# SERDES_16G0 register map
Vendor: Texas Instruments
Peripheral module from a debugger description file (folder J7ES).
Registers are 32-bit, read-write, reset 0x0 unless marked. A register's access mark holds for its fields unless they carry their own. Offsets are as the file gives them; lines under a group give offsets from that group; [hi:lo] are bit positions; {n}, {i} and the like mark numbered series; 'fields as' and 'values as' point back to an identical list; <NAME> marks a mode.

## SERDES_16G0 (part 1 of 5)
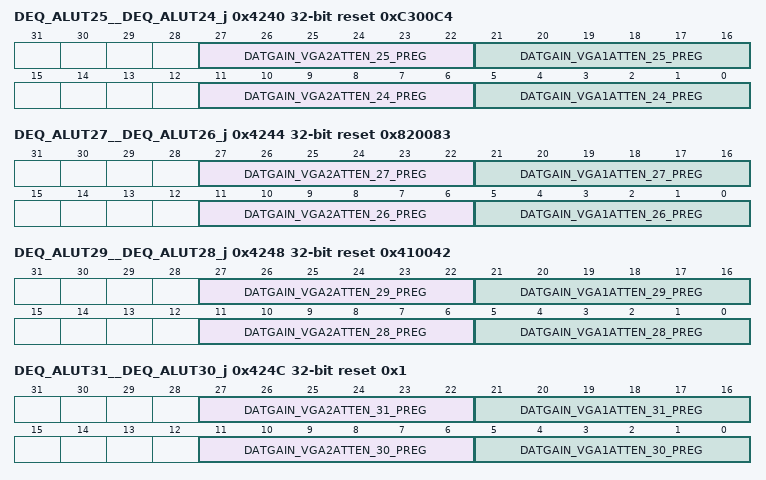
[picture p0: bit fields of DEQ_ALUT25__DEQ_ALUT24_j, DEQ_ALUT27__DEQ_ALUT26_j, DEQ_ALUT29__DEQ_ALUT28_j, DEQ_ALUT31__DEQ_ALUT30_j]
0x4240 DEQ_ALUT25__DEQ_ALUT24_j reset 0xC300C4 — Receive data path equalization LUT attenuation, entry 24 register. Offset = 4240h + (j * 400h); where j = 0h to 1h
  [27:22] DATGAIN_VGA2ATTEN_25_PREG — Receive data path equalization LUT VGA2 attenuation control, entry 25
  [21:16] DATGAIN_VGA1ATTEN_25_PREG — Receive data path equalization LUT VGA1 attenuation control, entry 25
  [11:6] DATGAIN_VGA2ATTEN_24_PREG — Receive data path equalization LUT VGA2 attenuation control, entry 24
  [5:0] DATGAIN_VGA1ATTEN_24_PREG — Receive data path equalization LUT VGA1 attenuation control, entry 24
0x4244 DEQ_ALUT27__DEQ_ALUT26_j reset 0x820083 — Receive data path equalization LUT attenuation, entry 26 register. Offset = 4244h + (j * 400h); where j = 0h to 1h
  [27:22] DATGAIN_VGA2ATTEN_27_PREG — Receive data path equalization LUT VGA2 attenuation control, entry 27
  [21:16] DATGAIN_VGA1ATTEN_27_PREG — Receive data path equalization LUT VGA1 attenuation control, entry 27
  [11:6] DATGAIN_VGA2ATTEN_26_PREG — Receive data path equalization LUT VGA2 attenuation control, entry 26
  [5:0] DATGAIN_VGA1ATTEN_26_PREG — Receive data path equalization LUT VGA1 attenuation control, entry 26
0x4248 DEQ_ALUT29__DEQ_ALUT28_j reset 0x410042 — Receive data path equalization LUT attenuation, entry 28 register. Offset = 4248h + (j * 400h); where j = 0h to 1h
  [27:22] DATGAIN_VGA2ATTEN_29_PREG — Receive data path equalization LUT VGA2 attenuation control, entry 29
  [21:16] DATGAIN_VGA1ATTEN_29_PREG — Receive data path equalization LUT VGA1 attenuation control, entry 29
  [11:6] DATGAIN_VGA2ATTEN_28_PREG — Receive data path equalization LUT VGA2 attenuation control, entry 28
  [5:0] DATGAIN_VGA1ATTEN_28_PREG — Receive data path equalization LUT VGA1 attenuation control, entry 28
0x424C DEQ_ALUT31__DEQ_ALUT30_j reset 0x1 — Receive data path equalization LUT attenuation, entry 30 register. Offset = 424Ch + (j * 400h); where j = 0h to 1h
  [27:22] DATGAIN_VGA2ATTEN_31_PREG — Receive data path equalization LUT VGA2 attenuation control, entry 31
  [21:16] DATGAIN_VGA1ATTEN_31_PREG — Receive data path equalization LUT VGA1 attenuation control, entry 31
  [11:6] DATGAIN_VGA2ATTEN_30_PREG — Receive data path equalization LUT VGA2 attenuation control, entry 30
  [5:0] DATGAIN_VGA1ATTEN_30_PREG — Receive data path equalization LUT VGA1 attenuation control, entry 30
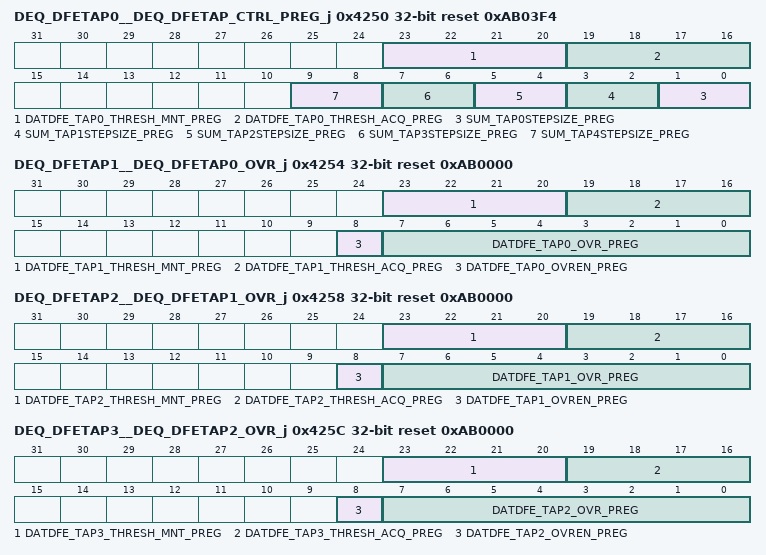
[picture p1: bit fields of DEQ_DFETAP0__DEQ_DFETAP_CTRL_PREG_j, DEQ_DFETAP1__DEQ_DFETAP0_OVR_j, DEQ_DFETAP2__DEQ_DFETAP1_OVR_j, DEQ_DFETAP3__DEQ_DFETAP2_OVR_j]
0x4250 DEQ_DFETAP0__DEQ_DFETAP_CTRL_PREG_j reset 0xAB03F4 — Receive data path DFE tap control register. Offset = 4250h + (j * 400h); where j = 0h to 1h
  [23:20] DATDFE_TAP0_THRESH_MNT_PREG — Receive data path DFE tap 0 accumulator threshold for maintenance.
  [19:16] DATDFE_TAP0_THRESH_ACQ_PREG — Receive data path DFE tap 0 accumulator threshold for acquisition.
  [2n+1:2n] SUM_TAP{n}STEPSIZE_PREG (n=0..4) — Receive data path DFE tap {n} feedback current trim:
0x4254 DEQ_DFETAP1__DEQ_DFETAP0_OVR_j reset 0xAB0000 — Receive data path DFE tap 0 override register. Offset = 4254h + (j * 400h); where j = 0h to 1h
  [23:20] DATDFE_TAP1_THRESH_MNT_PREG — Receive data path DFE tap 1 accumulator threshold for maintenance.
  [19:16] DATDFE_TAP1_THRESH_ACQ_PREG — Receive data path DFE tap 1 accumulator threshold for acquisition.
  [8] DATDFE_TAP0_OVREN_PREG — Receive data path DFE tap 0 weight active high override enable.
  [7:0] DATDFE_TAP0_OVR_PREG — When datdfe_tap0_ovren_preg is asserted high, this value overrides the tap 0 weight.
0x4258 DEQ_DFETAP2__DEQ_DFETAP1_OVR_j reset 0xAB0000 — Receive data path DFE tap 1 override register. Offset = 4258h + (j * 400h); where j = 0h to 1h
  [23:20] DATDFE_TAP2_THRESH_MNT_PREG — Receive data path DFE tap 2 accumulator threshold for maintenance.
  [19:16] DATDFE_TAP2_THRESH_ACQ_PREG — Receive data path DFE tap 2 accumulator threshold for acquisition.
  [8] DATDFE_TAP1_OVREN_PREG — Receive data path DFE tap 1 weight active high override enable.
  [7:0] DATDFE_TAP1_OVR_PREG — When datdfe_tap1_ovren_preg is asserted high, this value overrides the tap 1 weight.
0x425C DEQ_DFETAP3__DEQ_DFETAP2_OVR_j reset 0xAB0000 — Receive data path DFE tap 2 override register. Offset = 425Ch + (j * 400h); where j = 0h to 1h
  [23:20] DATDFE_TAP3_THRESH_MNT_PREG — Receive data path DFE tap 3 accumulator threshold for maintenance.
  [19:16] DATDFE_TAP3_THRESH_ACQ_PREG — Receive data path DFE tap 3 accumulator threshold for acquisition.
  [8] DATDFE_TAP2_OVREN_PREG — Receive data path DFE tap 2 weight active high override enable.
  [7:0] DATDFE_TAP2_OVR_PREG — When datdfe_tap2_ovren_preg is asserted high, this value overrides the tap 2 weight.
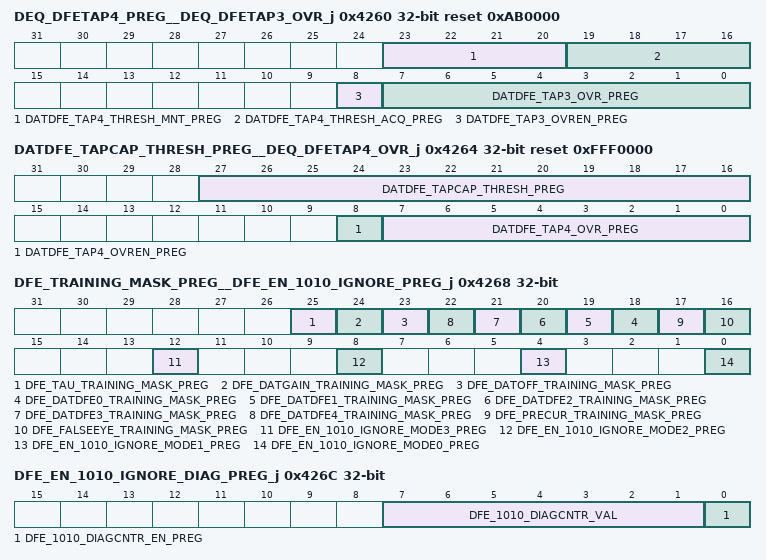
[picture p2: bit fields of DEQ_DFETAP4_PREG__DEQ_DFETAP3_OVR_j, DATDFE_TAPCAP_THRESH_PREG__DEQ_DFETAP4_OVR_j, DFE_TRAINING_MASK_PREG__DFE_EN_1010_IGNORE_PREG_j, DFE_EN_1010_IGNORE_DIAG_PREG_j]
0x4260 DEQ_DFETAP4_PREG__DEQ_DFETAP3_OVR_j reset 0xAB0000 — Receive data path DFE tap 3 override register. Offset = 4260h + (j * 400h); where j = 0h to 1h
  [23:20] DATDFE_TAP4_THRESH_MNT_PREG — Receive data path DFE tap 4 accumulator threshold for maintenance.
  [19:16] DATDFE_TAP4_THRESH_ACQ_PREG — Receive data path DFE tap 4 accumulator threshold for acquisition.
  [8] DATDFE_TAP3_OVREN_PREG — Receive data path DFE tap 3 weight active high override enable.
  [7:0] DATDFE_TAP3_OVR_PREG — When datdfe_tap3_ovren_preg is asserted high, this value overrides the tap 3 weight.
0x4264 DATDFE_TAPCAP_THRESH_PREG__DEQ_DFETAP4_OVR_j reset 0xFFF0000 — Receive data path DFE tap 4 override register. Offset = 4264h + (j * 400h); where j = 0h to 1h
  [27:16] DATDFE_TAPCAP_THRESH_PREG — Threshold for capping the sum of the receive data path DFE tap magnitudes.
  [8] DATDFE_TAP4_OVREN_PREG — Receive data path DFE tap 4 weight active high override enable.
  [7:0] DATDFE_TAP4_OVR_PREG — When datdfe_tap4_ovren_preg is asserted high, this value overrides the tap 4 weight.
0x4268 DFE_TRAINING_MASK_PREG__DFE_EN_1010_IGNORE_PREG_j — DFE_TRAINING_MASK_PREG__DFE_EN_1010_IGNORE_PREG Offset = 4268h + (j * 400h); where j = 0h to 1h
  [25] DFE_TAU_TRAINING_MASK_PREG — When set to 1'b0, the tau training will be paused during rx_eq_training_data_valid deassertion and during detection of 1010 pattern occurs with dfe_en_1010_ignore_modeX_preg is asserted.
  [24] DFE_DATGAIN_TRAINING_MASK_PREG — When set to 1'b0, the data path gain training will be paused during rx_eq_training_data_valid deassertion and during detection of 1010 pattern occurs with dfe_en_1010_ignore_modeX_preg is asserted.
  [23] DFE_DATOFF_TRAINING_MASK_PREG — When set to 1'b0, the data path offset training will be paused during rx_eq_training_data_valid deassertion and during detection of 1010 pattern occurs with dfe_en_1010_ignore_modeX_preg is asserted.
  [n+18] DFE_DATDFE{n}_TRAINING_MASK_PREG (n=0..4) — When set to 1'b0, the DFE tap {n} training will be paused during rx_eq_training_data_valid deassertion and during detection of 1010 pattern occurs with dfe_en_1010_ignore_modeX_preg is asserted.
  [17] DFE_PRECUR_TRAINING_MASK_PREG — When set to 1'b0, the far-end transmit pre cursor training will be paused during rx_eq_training_data_valid deassertion and during detection of 1010 pattern occurs with dfe_en_1010_ignore_modeX_preg is asserted.
  [16] DFE_FALSEEYE_TRAINING_MASK_PREG — When set to 1'b0, false eye detection will be paused during rx_eq_training_data_valid deassertion and during detection of 1010 pattern occurs with dfe_en_1010_ignore_modeX_preg is asserted.
  [12] DFE_EN_1010_IGNORE_MODE3_PREG — Active high enable for the DFE ignore 1010 function when xcvr_standard_mode_ln_{15:0}[2:0] is 3'b011.
  [8] DFE_EN_1010_IGNORE_MODE2_PREG — Active high enable for the DFE ignore 1010 function when xcvr_standard_mode_ln_{15:0}[2:0] is 3'b010.
  [4] DFE_EN_1010_IGNORE_MODE1_PREG — Active high enable for the DFE ignore 1010 function when xcvr_standard_mode_ln_{15:0}[2:0] is 3'b001
  [0] DFE_EN_1010_IGNORE_MODE0_PREG — Active high enable for the DFE ignore 1010 function when xcvr_standard_mode_ln_{15:0}[2:0] is 3'b000.
0x426C DFE_EN_1010_IGNORE_DIAG_PREG_j access per field — DFE_EN_1010_IGNORE_DIAG_PREG Offset = 426Ch + (j * 400h); where j = 0h to 1h
  [7:1] DFE_1010_DIAGCNTR_VAL ro — Indicates how many 1010.. or 0101.. pattern words are detected
  [0] DFE_1010_DIAGCNTR_EN_PREG rw — Level sensitive diagnostic bit: When de-asserted, counter will be cleared and will not advance.
0x4270 DEQ_PRECUR_PREG_j reset 0x8 — Receive data path far-end transmit precursor equalization control register. Offset = 4270h + (j * 400h); where j = 0h to 1h
  [3:0] PRECUR_THRESH_PREG — Receive data path far-end transmit precursor equalization accumulator threshold.
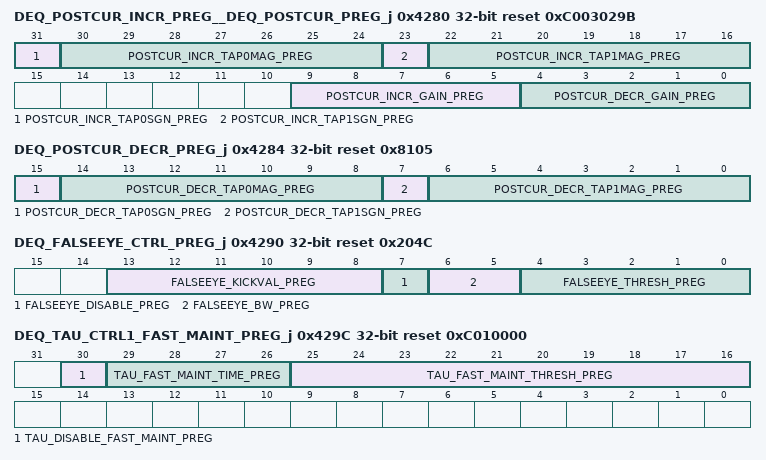
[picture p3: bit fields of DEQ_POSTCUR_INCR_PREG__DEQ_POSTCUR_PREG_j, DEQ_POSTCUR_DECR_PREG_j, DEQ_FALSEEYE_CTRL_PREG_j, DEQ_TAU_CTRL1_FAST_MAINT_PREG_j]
0x4280 DEQ_POSTCUR_INCR_PREG__DEQ_POSTCUR_PREG_j reset 0xC003029B — Receive data path far-end transmit postcursor equalization control register. Offset = 4280h + (j * 400h); where j = 0h to 1h
  [31] POSTCUR_INCR_TAP0SGN_PREG — Receive data path far-end transmit postcursor equalization increment request tap 0 threshold sign.
  [30:24] POSTCUR_INCR_TAP0MAG_PREG — Receive data path far-end transmit postcursor equalization increment request tap 0 threshold unsigned binary encoded magnitude.
  [23] POSTCUR_INCR_TAP1SGN_PREG — Receive data path far-end transmit postcursor equalization increment request tap 1 threshold sign.
  [22:16] POSTCUR_INCR_TAP1MAG_PREG — Receive data path far-end transmit postcursor equalization increment request tap 1 threshold unsigned binary encoded magnitude.
  [9:5] POSTCUR_INCR_GAIN_PREG — Receive data path far-end transmit postcursor equalization increment request gain threshold.
  [4:0] POSTCUR_DECR_GAIN_PREG — Receive data path far-end transmit postcursor equalization decrement request gain threshold.
0x4284 DEQ_POSTCUR_DECR_PREG_j reset 0x8105 — Receive data path far-end transmit postcursor equalization decrement control register. Offset = 4284h + (j * 400h); where j = 0h to 1h
  [15] POSTCUR_DECR_TAP0SGN_PREG — Receive data path far-end transmit postcursor equalization decrement request tap 0 threshold sign.
  [14:8] POSTCUR_DECR_TAP0MAG_PREG — Receive data path far-end transmit postcursor equalization decrement request tap 0 threshold unsigned binary encoded magnitude.
  [7] POSTCUR_DECR_TAP1SGN_PREG — Receive data path far-end transmit postcursor equalization decrement request tap 1 threshold sign.
  [6:0] POSTCUR_DECR_TAP1MAG_PREG — Receive data path far-end transmit postcursor equalization decrement request tap 1 threshold unsigned binary encoded magnitude.
0x4290 DEQ_FALSEEYE_CTRL_PREG_j reset 0x204C — Receive data path equalization (DEQ) false eye control register. Offset = 4290h + (j * 400h); where j = 0h to 1h
  [13:8] FALSEEYE_KICKVAL_PREG — Receive data path equalization (DEQ) false eye detection phase kick amplitude.
  [7] FALSEEYE_DISABLE_PREG — Receive data path equalization (DEQ) false eye detection active high disable.
  [6:5] FALSEEYE_BW_PREG — Receive data path equalization (DEQ) false eye detection bandwidth selection.
  [4:0] FALSEEYE_THRESH_PREG — Receive data path equalization (DEQ) false eye detection binary encoded threshold.
0x429C DEQ_TAU_CTRL1_FAST_MAINT_PREG_j reset 0xC010000 — Receive data path equalization (DEQ) fast maintenance tau training control register 1. Offset = 429Ch + (j * 400h); where j = 0h to 1h
  [30] TAU_DISABLE_FAST_MAINT_PREG — Receive data path equalization (DEQ) fast maintenance tau algorithm active high disable.
  [29:26] TAU_FAST_MAINT_TIME_PREG — Receive data path equalization (DEQ) fast maintenance tau algorithm accumulation time.
  [25:16] TAU_FAST_MAINT_THRESH_PREG — Receive data path equalization (DEQ) fast maintainance tau algorithm accumulation threshold.
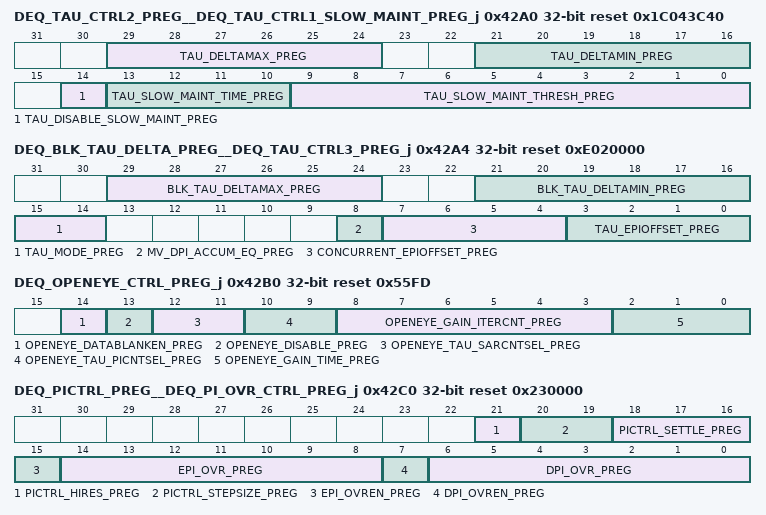
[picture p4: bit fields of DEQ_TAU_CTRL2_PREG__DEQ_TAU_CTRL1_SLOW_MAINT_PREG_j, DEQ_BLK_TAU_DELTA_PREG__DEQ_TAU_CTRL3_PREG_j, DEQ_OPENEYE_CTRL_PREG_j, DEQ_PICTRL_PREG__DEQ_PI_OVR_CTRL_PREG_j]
0x42A0 DEQ_TAU_CTRL2_PREG__DEQ_TAU_CTRL1_SLOW_MAINT_PREG_j reset 0x1C043C40 — Receive data path equalization (DEQ) slow maintenance tau training control register 1. Offset = 42A0h + (j * 400h); where j = 0h to 1h
  [29:24] TAU_DELTAMAX_PREG — Receive data path equalization (DEQ) tau algorithm maximum delta from EPI to DPI.
  [21:16] TAU_DELTAMIN_PREG — Receive data path equalization (DEQ) tau algorithm minimum delta from EPI to DPI.
  [14] TAU_DISABLE_SLOW_MAINT_PREG — Receive data path equalization (DEQ) slow maintenance tau algorithm active high disable.
  [13:10] TAU_SLOW_MAINT_TIME_PREG — Receive data path equalization (DEQ) slow maintenance tau algorithm accumulation time
  [9:0] TAU_SLOW_MAINT_THRESH_PREG — Receive data path equalization (DEQ) slow maintenance tau algorithm accumulation threshold.
0x42A4 DEQ_BLK_TAU_DELTA_PREG__DEQ_TAU_CTRL3_PREG_j reset 0xE020000 — DEQ_BLK_TAU_DELTA_PREG__DEQ_TAU_CTRL3_PREG Offset = 42A4h + (j * 400h); where j = 0h to 1h
  [29:24] BLK_TAU_DELTAMAX_PREG — Receive data path equalization (DEQ) tau algorithm's maximum delta from EPI to DPI used for block TAU acquisition and apparent center.
  [21:16] BLK_TAU_DELTAMIN_PREG — Receive data path equalization (DEQ) tau algorithm's minimum delta from EPI to DPI used for block TAU acquisition and apparent center.
  [15:14] TAU_MODE_PREG — TAU mode register
  [8] MV_DPI_ACCUM_EQ_PREG — Move DPI to the left if (r_accum_a is equal to r_accum_b) and (r_delta is less than equal to tau_deltamin_preg) if this bit is set to 1'b1, else don't move DPI.
  [7:4] CONCURRENT_EPIOFFSET_PREG — Receive data path equalization (DEQ) tau algorithm 4 bit signed offset for EPI used in concurrent, eyesurf, and rx margining.
  [3:0] TAU_EPIOFFSET_PREG — Receive data path equalization (DEQ) tau algorithm 4 bit signed offset for EPI used tau opertions.
0x42B0 DEQ_OPENEYE_CTRL_PREG_j reset 0x55FD — Receive data path equalization (DEQ) open eye algorithms control register. Offset = 42B0h + (j * 400h); where j = 0h to 1h
  [14] OPENEYE_DATABLANKEN_PREG — Receive data path equalization (DEQ) open eye data blank active high enable.
  [13] OPENEYE_DISABLE_PREG — Receive data path equalization (DEQ) open eye tau algorithm active high disable.
  [12:11] OPENEYE_TAU_SARCNTSEL_PREG — Receive data path equalization (DEQ) open eye tau algorithm SAR count selection.
  [10:9] OPENEYE_TAU_PICNTSEL_PREG — Receive data path equalization (DEQ) open eye tau algorithm PI step count selection.
  [8:3] OPENEYE_GAIN_ITERCNT_PREG — Open eye gain iteration count
  [2:0] OPENEYE_GAIN_TIME_PREG — Open eye gain accumulation time.
0x42C0 DEQ_PICTRL_PREG__DEQ_PI_OVR_CTRL_PREG_j reset 0x230000 — Receive data path equalization (DEQ) PI override register. Offset = 42C0h + (j * 400h); where j = 0h to 1h
  [21] PICTRL_HIRES_PREG — DPI and EPI high resolution enable:
  [20:19] PICTRL_STEPSIZE_PREG — DPI and EPI step size selection.
  [18:16] PICTRL_SETTLE_PREG — DPI and EPI control settling time.
  [15] EPI_OVREN_PREG — EPI phase active high override enable.
  [14:8] EPI_OVR_PREG — When epi_ovren_preg is asserted high, this value will override the data path EPI binary phase.
  [7] DPI_OVREN_PREG — DPI phase active high override enable.
  [6:0] DPI_OVR_PREG — When dpi_ovren_preg is asserted high, this value will override the data path DPI binary phase.
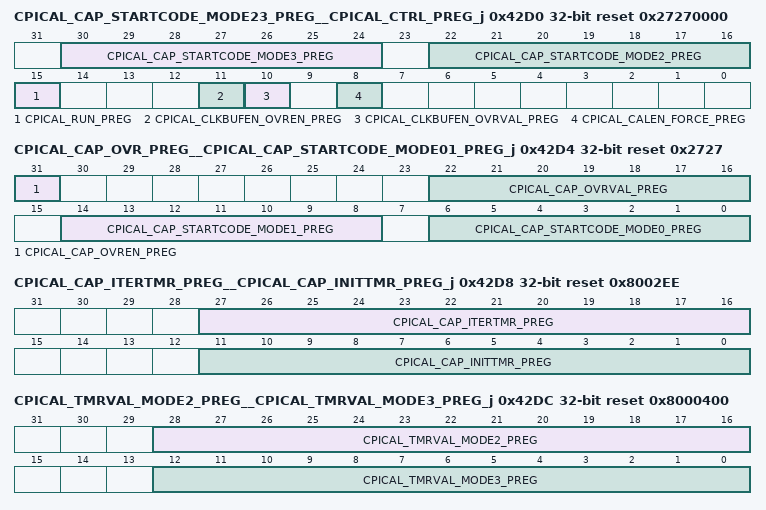
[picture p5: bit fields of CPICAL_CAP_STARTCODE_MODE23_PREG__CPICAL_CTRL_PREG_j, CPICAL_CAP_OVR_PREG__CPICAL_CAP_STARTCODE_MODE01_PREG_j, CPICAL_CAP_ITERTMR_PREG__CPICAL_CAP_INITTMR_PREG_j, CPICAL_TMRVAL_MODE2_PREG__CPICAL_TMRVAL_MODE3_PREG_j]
0x42D0 CPICAL_CAP_STARTCODE_MODE23_PREG__CPICAL_CTRL_PREG_j reset 0x27270000 — CPI calibration control and status register. Offset = 42D0h + (j * 400h); where j = 0h to 1h
  [30:24] CPICAL_CAP_STARTCODE_MODE3_PREG — This value is used as the starting code for subsequent CPI calibrations (capacitor) when xcvr_standard_mode_ln{15:0}[2:0] is 3'b011.
  [22:16] CPICAL_CAP_STARTCODE_MODE2_PREG — This value is used as the starting code for subsequent CPI calibrations(capacitor) when xcvr_standard_mode_ln{15:0}[2:0] is 3'b010.
  [15] CPICAL_RUN_PREG — CPI calibration manual initiation active high enable.
  [11] CPICAL_CLKBUFEN_OVREN_PREG — overide enable for cpi cal clock buf enable
  [10] CPICAL_CLKBUFEN_OVRVAL_PREG — overide value for cpi cal clock buf enable
  [8] CPICAL_CALEN_FORCE_PREG — CPI analog module calen force.
0x42D4 CPICAL_CAP_OVR_PREG__CPICAL_CAP_STARTCODE_MODE01_PREG_j reset 0x2727 — CPI calibration (capacitor) starting code register for xcvr_standard_mode 0 and 1. Offset = 42D4h + (j * 400h); where j = 0h to 1h
  [31] CPICAL_CAP_OVREN_PREG — CPI calibration (capacitor) override active high enable.
  [22:16] CPICAL_CAP_OVRVAL_PREG — When cpical_cap_ovren_preg is asserted high, this value is used by the CPI rather than the calibration engine result.
  [14:8] CPICAL_CAP_STARTCODE_MODE1_PREG — This value is used as the starting code for subsequent CPI calibrations(capacitor) when xcvr_standard_mode_ln{15:0}[2:0] is 3'b001.
  [6:0] CPICAL_CAP_STARTCODE_MODE0_PREG — This value is used as the starting code for subsequent CPI calibrations(capacitor) when xcvr_standard_mode_ln{15:0}[2:0] is 3'b000.
0x42D8 CPICAL_CAP_ITERTMR_PREG__CPICAL_CAP_INITTMR_PREG_j reset 0x8002EE — CPI calibration(capacitor) initial delay register. Offset = 42D8h + (j * 400h); where j = 0h to 1h
  [27:16] CPICAL_CAP_ITERTMR_PREG — CPI calibration(capacitor) iteration wait timer to allow the analog circuits to settle to the new frequency after a calibration code change.
  [11:0] CPICAL_CAP_INITTMR_PREG — CPI calibration(capacitor) initial wait timer to allow the analog circuits to settle on initiation of the calibration sequence.
0x42DC CPICAL_TMRVAL_MODE2_PREG__CPICAL_TMRVAL_MODE3_PREG_j reset 0x8000400 — CPI calibration mode3 evaluation time register Offset = 42DCh + (j * 400h); where j = 0h to 1h
  [28:16] CPICAL_TMRVAL_MODE2_PREG — This value sets the Lane Standards Decoder frequency evaluation time.
  [12:0] CPICAL_TMRVAL_MODE3_PREG — This value sets the Lane Standards Decoder frequency evaluation time.
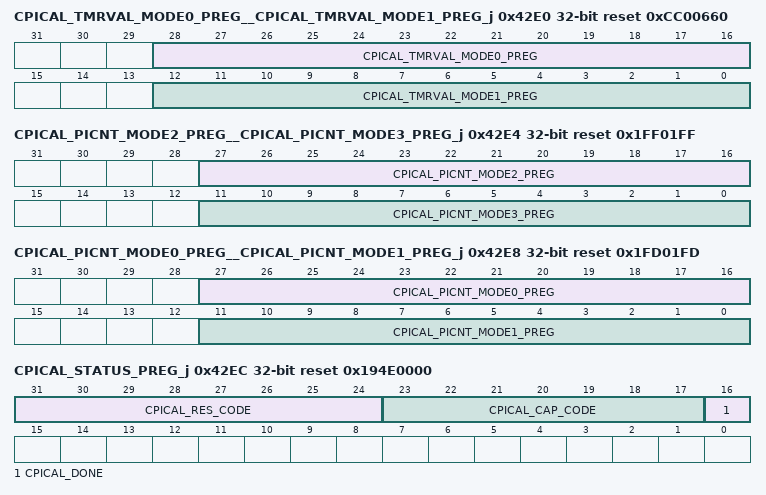
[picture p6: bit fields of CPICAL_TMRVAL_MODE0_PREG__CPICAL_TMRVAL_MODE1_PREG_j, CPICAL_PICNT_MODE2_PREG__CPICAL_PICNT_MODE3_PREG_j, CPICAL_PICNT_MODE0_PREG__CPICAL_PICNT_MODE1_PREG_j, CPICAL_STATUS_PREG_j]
0x42E0 CPICAL_TMRVAL_MODE0_PREG__CPICAL_TMRVAL_MODE1_PREG_j reset 0xCC00660 — CPI calibration mode1 evaluation time register Offset = 42E0h + (j * 400h); where j = 0h to 1h
  [28:16] CPICAL_TMRVAL_MODE0_PREG — This value sets the Lane Standards Decoder frequency evaluation time.
  [12:0] CPICAL_TMRVAL_MODE1_PREG — This value sets the Lane Standards Decoder frequency evaluation time.
0x42E4 CPICAL_PICNT_MODE2_PREG__CPICAL_PICNT_MODE3_PREG_j reset 0x1FF01FF — CPI calibration PI clock cnt, mode 3 register. Offset = 42E4h + (j * 400h); where j = 0h to 1h
  [27:16] CPICAL_PICNT_MODE2_PREG — This value sets the Lane Standards Decoder PI clock counter expected value when xcvr_standard_mode_ln{15:0}[2:0] is 3'b010.
  [11:0] CPICAL_PICNT_MODE3_PREG — This value sets the Lane Standards Decoder PI clock counter expected value when xcvr_standard_mode_ln{15:0}[2:0] is 3'b011.
0x42E8 CPICAL_PICNT_MODE0_PREG__CPICAL_PICNT_MODE1_PREG_j reset 0x1FD01FD — CPI calibration PI clock cnt, mode 1 register. Offset = 42E8h + (j * 400h); where j = 0h to 1h
  [27:16] CPICAL_PICNT_MODE0_PREG — This value sets the Lane Standards Decoder PI clock counter expected value when xcvr_standard_mode_ln{15:0}[2:0] is 3'b000.
  [11:0] CPICAL_PICNT_MODE1_PREG — This value sets the Lane Standards Decoder PI clock counter expected value when xcvr_standard_mode_ln{15:0}[2:0] is 3'b001.
0x42EC CPICAL_STATUS_PREG_j ro reset 0x194E0000 — Fine PI calibration control and status register Offset = 42ECh + (j * 400h); where j = 0h to 1h
  [31:24] CPICAL_RES_CODE — CPI calibration resistor code.
  [23:17] CPICAL_CAP_CODE — CPI calibration capacitor code.
  [16] CPICAL_DONE — CPI calibration active high complete flag.
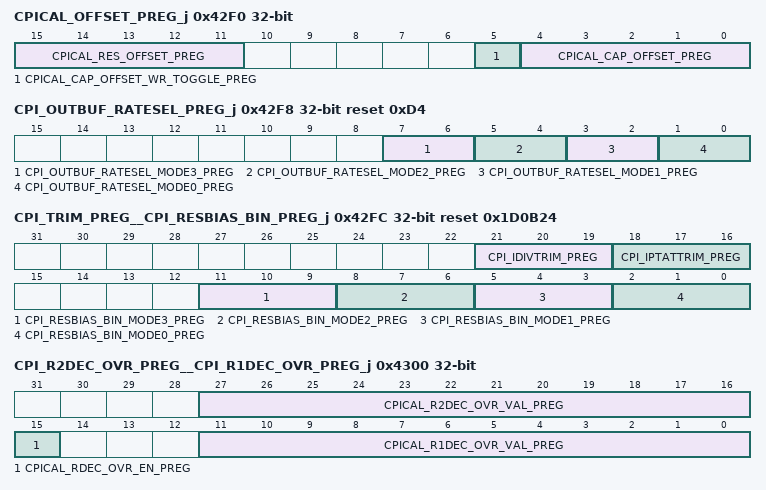
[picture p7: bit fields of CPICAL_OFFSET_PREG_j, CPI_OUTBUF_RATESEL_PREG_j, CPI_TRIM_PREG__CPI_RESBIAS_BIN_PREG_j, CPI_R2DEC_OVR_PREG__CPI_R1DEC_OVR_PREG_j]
0x42F0 CPICAL_OFFSET_PREG_j access per field — CPI calibration offset register(resistor and capacitor) Offset = 42F0h + (j * 400h); where j = 0h to 1h
  [15:11] CPICAL_RES_OFFSET_PREG rw — Twos compliment offset to be added to the calibrated course code sent to the CPI .
  [5] CPICAL_CAP_OFFSET_WR_TOGGLE_PREG wo — Cal (cap)Offset write toggle bit
  [4:0] CPICAL_CAP_OFFSET_PREG rw — Twos compliment offset to be added to the calibrated course code sent to the CPI.
0x42F8 CPI_OUTBUF_RATESEL_PREG_j reset 0xD4 — CPI output buffers BW control Offset = 42F8h + (j * 400h); where j = 0h to 1h
  [7:6] CPI_OUTBUF_RATESEL_MODE3_PREG — CPI output buffers BW control when xcvr_standard_mode_ln{15:0}[2:0] is 3'b011.
  [5:4] CPI_OUTBUF_RATESEL_MODE2_PREG — CPI output buffers BW control when xcvr_standard_mode_ln{15:0}[2:0] is 3'b010.
  [3:2] CPI_OUTBUF_RATESEL_MODE1_PREG — CPI output buffers BW control when xcvr_standard_mode_ln{15:0}[2:0] is 3'b001.
  [1:0] CPI_OUTBUF_RATESEL_MODE0_PREG — CPI output buffers BW control when xcvr_standard_mode_ln{15:0}[2:0] is 3'b000.
0x42FC CPI_TRIM_PREG__CPI_RESBIAS_BIN_PREG_j reset 0x1D0B24 — CPI res bias Offset = 42FCh + (j * 400h); where j = 0h to 1h
  [21:19] CPI_IDIVTRIM_PREG — bias current magnitude controll
  [18:16] CPI_IPTATTRIM_PREG — ptat percentage control
  [11:9] CPI_RESBIAS_BIN_MODE3_PREG — CPI res bias when xcvr_standard_mode_ln{15:0}[2:0] is 3'b011.
  [8:6] CPI_RESBIAS_BIN_MODE2_PREG — CPI res bias when xcvr_standard_mode_ln{15:0}[2:0] is 3'b010.
  [5:3] CPI_RESBIAS_BIN_MODE1_PREG — CPI res bias when xcvr_standard_mode_ln{15:0}[2:0] is 3'b001.
  [2:0] CPI_RESBIAS_BIN_MODE0_PREG — CPI res bias when xcvr_standard_mode_ln{15:0}[2:0] is 3'b000.
0x4300 CPI_R2DEC_OVR_PREG__CPI_R1DEC_OVR_PREG_j — CPI_R2DEC_OVR_PREG__CPI_R1DEC_OVR_PREG Offset = 4300h + (j * 400h); where j = 0h to 1h
  [27:16] CPICAL_R2DEC_OVR_VAL_PREG — Overide value for cpi cal resistor decoder 2 output
  [15] CPICAL_RDEC_OVR_EN_PREG — Overide enable for cpi cal resistor decoder 1 /2 (r1dec and r2dec) outputs.
  [11:0] CPICAL_R1DEC_OVR_VAL_PREG — Overide value for cpi cal resistor decoder 1 output
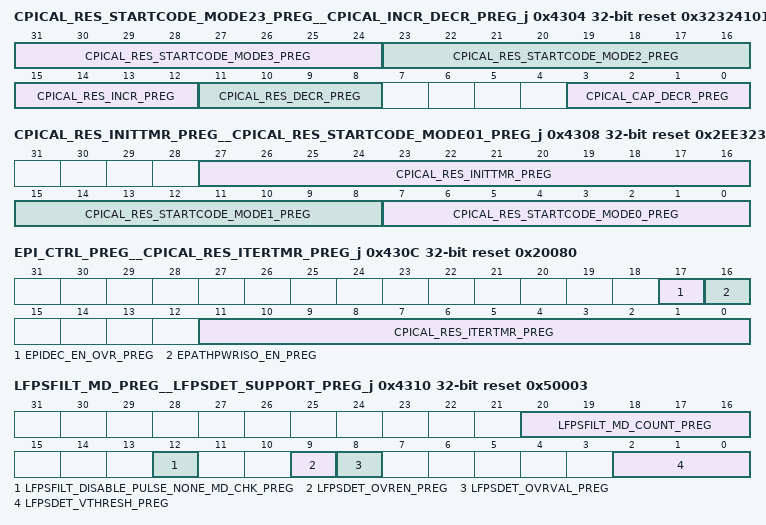
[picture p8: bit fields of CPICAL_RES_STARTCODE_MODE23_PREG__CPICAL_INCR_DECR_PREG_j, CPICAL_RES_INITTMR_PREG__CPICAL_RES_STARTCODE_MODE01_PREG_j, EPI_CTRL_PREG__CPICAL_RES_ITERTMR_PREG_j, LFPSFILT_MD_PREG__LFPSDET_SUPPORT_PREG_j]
0x4304 CPICAL_RES_STARTCODE_MODE23_PREG__CPICAL_INCR_DECR_PREG_j reset 0x32324101 — CPICAL_RES_STARTCODE_MODE23_PREG__CPICAL_INCR_DECR_PREG Offset = 4304h + (j * 400h); where j = 0h to 1h
  [31:24] CPICAL_RES_STARTCODE_MODE3_PREG — This value is used as the starting code for subsequent CPI calibrations (resistor) when xcvr_standard_mode_ln{15:0}[2:0] is 3'b011.
  [23:16] CPICAL_RES_STARTCODE_MODE2_PREG — This value is used as the starting code for subsequent CPI calibrations(resistor) when xcvr_standard_mode_ln{15:0}[2:0] is 3'b010.
  [15:12] CPICAL_RES_INCR_PREG — CPI calibration Resistor code steps up by this value while incrementing the code.
  [11:8] CPICAL_RES_DECR_PREG — CPI calibration Resistor code steps down by this value while decrementing the code.
  [3:0] CPICAL_CAP_DECR_PREG — CPI calibration Capacitor code steps down by this value while decrementing the code.
0x4308 CPICAL_RES_INITTMR_PREG__CPICAL_RES_STARTCODE_MODE01_PREG_j reset 0x2EE3232 — CPI calibration (resisitor) starting code register for xcvr_standard_mode 0 and 1. Offset = 4308h + (j * 400h); where j = 0h to 1h
  [27:16] CPICAL_RES_INITTMR_PREG — CPI calibration(resistor) initial wait timer to allow the analog circuits to settle on initiation of the calibration sequence.
  [15:8] CPICAL_RES_STARTCODE_MODE1_PREG — This value is used as the starting code for subsequent CPI calibrations (resistor) when xcvr_standard_mode_ln{15:0}[2:0] is 3'b0001
  [7:0] CPICAL_RES_STARTCODE_MODE0_PREG — This value is used as the starting code for subsequent CPI calibrations(resistor) when xcvr_standard_mode_ln{15:0}[2:0] is 3'b000.
0x430C EPI_CTRL_PREG__CPICAL_RES_ITERTMR_PREG_j reset 0x20080 — CPI calibration(resisitor)iteration delay register. Offset = 430Ch + (j * 400h); where j = 0h to 1h
  [17] EPIDEC_EN_OVR_PREG — EPI IDDQ style PSC enable override:
  [16] EPATHPWRISO_EN_PREG — EPI power island manual active high enable.
  [11:0] CPICAL_RES_ITERTMR_PREG — CPI calibration(resistor) iteration wait timer to allow the analog circuits to settle to the new frequency after a calibration code change.
0x4310 LFPSFILT_MD_PREG__LFPSDET_SUPPORT_PREG_j reset 0x50003 — LFPS Detector Support Register Offset = 4310h + (j * 400h); where j = 0h to 1h
  [20:16] LFPSFILT_MD_COUNT_PREG — Minimum pulse distance counter value (MD):
  [12] LFPSFILT_DISABLE_PULSE_NONE_MD_CHK_PREG — When asserted the MD check using pulse_none is disabled.
  [9] LFPSDET_OVREN_PREG — LFPS detect active high analog override enable.
  [8] LFPSDET_OVRVAL_PREG — When lfpsdet_ovren_preg is asserted high, this value drives the filter rather than the analog circuit result.
  [2:0] LFPSDET_VTHRESH_PREG — Voltage threshold control.
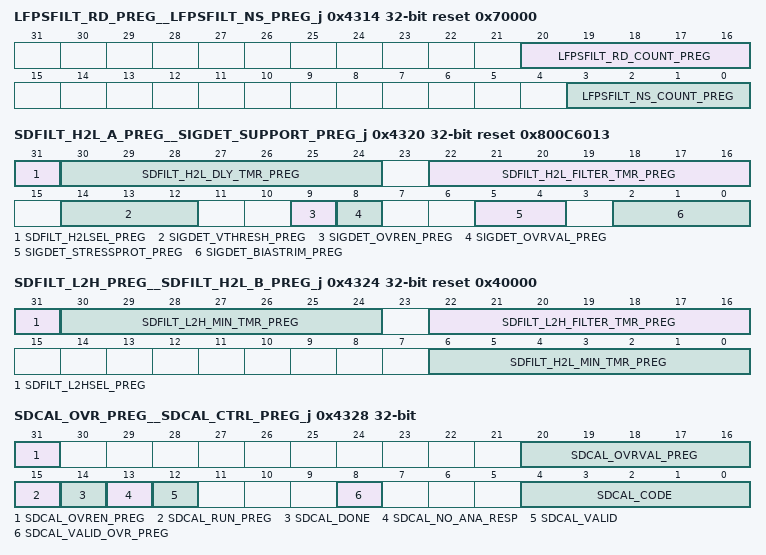
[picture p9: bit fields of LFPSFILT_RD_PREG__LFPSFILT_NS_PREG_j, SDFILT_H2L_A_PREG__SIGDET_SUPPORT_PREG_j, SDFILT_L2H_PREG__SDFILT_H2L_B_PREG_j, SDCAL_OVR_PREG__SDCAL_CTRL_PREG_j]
0x4314 LFPSFILT_RD_PREG__LFPSFILT_NS_PREG_j reset 0x70000 — LFPS Detection Filter No Signal Counter Register Offset = 4314h + (j * 400h); where j = 0h to 1h
  [20:16] LFPSFILT_RD_COUNT_PREG — Ramp down counter value (RD):
  [3:0] LFPSFILT_NS_COUNT_PREG — No signal counter value (NS):
0x4318 LFPSFILT_MP_PREG_j reset 0x7 — LFPS Detection Filter Minimum Pulse Duration Counter Register Offset = 4318h + (j * 400h); where j = 0h to 1h
  [2:0] LFPSFILT_MP_COUNT_PREG — Minimum pulse duration (MP):
0x4320 SDFILT_H2L_A_PREG__SIGDET_SUPPORT_PREG_j reset 0x800C6013 — Receive signal detection support register. Offset = 4320h + (j * 400h); where j = 0h to 1h
  [31] SDFILT_H2LSEL_PREG — Receive signal detect high to low filter select value:
  [30:24] SDFILT_H2L_DLY_TMR_PREG — Receive signal detect high to low filter delay timer value:
  [22:16] SDFILT_H2L_FILTER_TMR_PREG — Receive signal detect high to low filter timer value:
  [14:12] SIGDET_VTHRESH_PREG — Receive signal detection voltage threshold binary encoded selection:
  [9] SIGDET_OVREN_PREG — Receive signal detect active high analog override enable.
  [8] SIGDET_OVRVAL_PREG — When sigdet_ovren_preg is asserted high, this value drives the filter rather than the analog circuit result.
  [5:4] SIGDET_STRESSPROT_PREG — Receive signal detection analog device protection binary encoded selection:
  [2:0] SIGDET_BIASTRIM_PREG — Receive signal detection bias current binary encoded trim:
0x4324 SDFILT_L2H_PREG__SDFILT_H2L_B_PREG_j reset 0x40000 — Receive signal detection high to low filter control register B. Offset = 4324h + (j * 400h); where j = 0h to 1h
  [31] SDFILT_L2HSEL_PREG — Receive signal detect low to high filter select value:
  [30:24] SDFILT_L2H_MIN_TMR_PREG — Receive signal detect low to high filter minimum timer value:
  [22:16] SDFILT_L2H_FILTER_TMR_PREG — Receive signal detect low to high filter timer value:
  [6:0] SDFILT_H2L_MIN_TMR_PREG — Receive signal detect high to low filter minimum timer value:
0x4328 SDCAL_OVR_PREG__SDCAL_CTRL_PREG_j access per field — Receive signal detection calibration control register. Offset = 4328h + (j * 400h); where j = 0h to 1h
  [31] SDCAL_OVREN_PREG rw — Receive signal detect code active high override enable.
  [20:16] SDCAL_OVRVAL_PREG rw — When sdcal_ovren_preg is asserted high, this value overrides the internally signal detection calibration code from the calibration circuit.
  [15] SDCAL_RUN_PREG rw — Receive signal detection calibration manual start signal:
  [14] SDCAL_DONE ro — Receive signal detection calibration active high complete flag.
  [13] SDCAL_NO_ANA_RESP ro — Receive sigdet detection calibration no analog response flag.
  [12] SDCAL_VALID ro — Receive signal detection calibration has completed flag.
  [8] SDCAL_VALID_OVR_PREG rw — Receive signal detection calibration has completed override.
  [4:0] SDCAL_CODE ro — Receive signal detection calibration code.
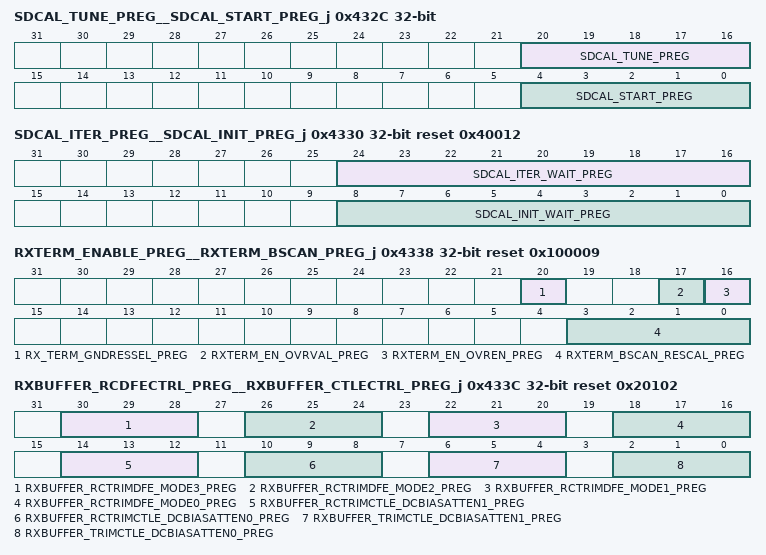
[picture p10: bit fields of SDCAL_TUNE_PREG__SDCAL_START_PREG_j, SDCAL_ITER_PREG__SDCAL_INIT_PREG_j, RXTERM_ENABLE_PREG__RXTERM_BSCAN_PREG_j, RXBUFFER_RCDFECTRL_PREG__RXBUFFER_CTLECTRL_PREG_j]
0x432C SDCAL_TUNE_PREG__SDCAL_START_PREG_j — Receive signal detection calibration starting code register. Offset = 432Ch + (j * 400h); where j = 0h to 1h
  [20:16] SDCAL_TUNE_PREG — Receive signal detection mission mode amplitude threshold binary encoded selection.
  [4:0] SDCAL_START_PREG — Receive signal detect calibration start code when the calibration sequence begins.
0x4330 SDCAL_ITER_PREG__SDCAL_INIT_PREG_j reset 0x40012 — Receive signal detection calibration initialization timer register. Offset = 4330h + (j * 400h); where j = 0h to 1h
  [24:16] SDCAL_ITER_WAIT_PREG — Receive signal detect calibration iteration wait timer providing delay for settling between each offset adjustment level change.
  [8:0] SDCAL_INIT_WAIT_PREG — Receive signal detect calibration initial wait timer providing a circuit settling period at the initiation of the calibration sequence.
0x4338 RXTERM_ENABLE_PREG__RXTERM_BSCAN_PREG_j reset 0x100009 — Receiver termination boundary scan support register Offset = 4338h + (j * 400h); where j = 0h to 1h
  [20] RX_TERM_GNDRESSEL_PREG — Receive termination configuration select.
  [17] RXTERM_EN_OVRVAL_PREG — Receive termination enable override value
  [16] RXTERM_EN_OVREN_PREG — Receive termination enable override enable
  [3:0] RXTERM_BSCAN_RESCAL_PREG — Receive termination resistor calibration level used in boundary scan operation.
0x433C RXBUFFER_RCDFECTRL_PREG__RXBUFFER_CTLECTRL_PREG_j reset 0x20102 — RX buffer CTLE control register Offset = 433Ch + (j * 400h); where j = 0h to 1h
  [30:28] RXBUFFER_RCTRIMDFE_MODE3_PREG — Trim for rxana_dfe path high frequency gain when xcvr_standard_mode_ln_{15:0}[2:0] is 3'b011.
  [26:24] RXBUFFER_RCTRIMDFE_MODE2_PREG — Trim for rxana_dfe path high frequency gain when xcvr_standard_mode_ln_{15:0}[2:0] is 3'b010.
  [22:20] RXBUFFER_RCTRIMDFE_MODE1_PREG — Trim for rxana_dfe path high frequency gain when xcvr_standard_mode_ln_{15:0}[2:0] is 3'b001.
  [18:16] RXBUFFER_RCTRIMDFE_MODE0_PREG — Trim for rxana_dfe path high frequency gain when xcvr_standard_mode_ln_{15:0}[2:0] is 3'b000.
  [14:12] RXBUFFER_RCTRIMCTLE_DCBIASATTEN1_PREG — Trim for rxana_ctleclk path high frequency gain when ctleclk_dcbiasatten is 1'b1.
  [10:8] RXBUFFER_RCTRIMCTLE_DCBIASATTEN0_PREG — Trim for rxana_ctleclk path high frequency gain when ctleclk_dcbiasatten is 1'b0.
  [6:4] RXBUFFER_TRIMCTLE_DCBIASATTEN1_PREG — Trim for rxana_ctleclk path DC gain when ctleclk_dcbiasatten is 1'b1.
  [2:0] RXBUFFER_TRIMCTLE_DCBIASATTEN0_PREG — Trim for rxana_ctleclk path DC gain when ctleclk_dcbiasatten is 1'b0.
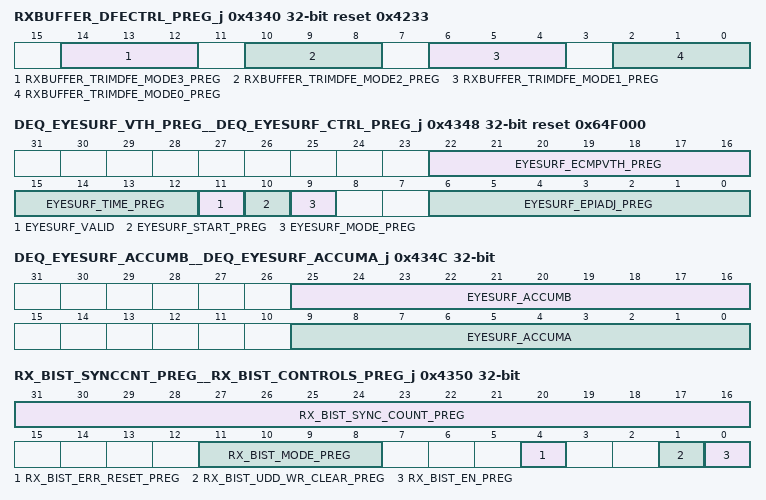
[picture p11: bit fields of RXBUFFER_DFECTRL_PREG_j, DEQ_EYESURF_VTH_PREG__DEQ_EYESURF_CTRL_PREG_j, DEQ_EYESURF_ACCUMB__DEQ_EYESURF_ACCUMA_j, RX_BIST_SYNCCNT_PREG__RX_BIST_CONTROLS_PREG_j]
0x4340 RXBUFFER_DFECTRL_PREG_j reset 0x4233 — RX buffer DFE control register Offset = 4340h + (j * 400h); where j = 0h to 1h
  [14:12] RXBUFFER_TRIMDFE_MODE3_PREG — Trim for rxana_dfe path DC gain when xcvr_standard_mode_ln_{15:0}[2:0] is 3'b011.
  [10:8] RXBUFFER_TRIMDFE_MODE2_PREG — Trim for rxana_dfe path DC gain when xcvr_standard_mode_ln_{15:0}[2:0] is 3'b010.
  [6:4] RXBUFFER_TRIMDFE_MODE1_PREG — Trim for rxana_dfe path DC gain when xcvr_standard_mode_ln_{15:0}[2:0] is 3'b001.
  [2:0] RXBUFFER_TRIMDFE_MODE0_PREG — Trim for rxana_dfe path DC gain when xcvr_standard_mode_ln_{15:0}[2:0] is 3'b000.
0x4348 DEQ_EYESURF_VTH_PREG__DEQ_EYESURF_CTRL_PREG_j access per field reset 0x64F000 — Receive data path eye surf control register. Offset = 4348h + (j * 400h); where j = 0h to 1h
  [22:16] EYESURF_ECMPVTH_PREG rw — Receive data path eye surf comparator voltage binary encoded threshold selection.
  [15:12] EYESURF_TIME_PREG rw — Receive data path eye surf accumulation time.
  [11] EYESURF_VALID ro — Receive data path eye surf accumulation period active high complete flag.
  [10] EYESURF_START_PREG rw — Receive data path eye surf active high start sequence enable
  [9] EYESURF_MODE_PREG rw — Receive data path eye surf active high mode enable.
  [6:0] EYESURF_EPIADJ_PREG rw — Receive data path eye surf EPI position shift control.
0x434C DEQ_EYESURF_ACCUMB__DEQ_EYESURF_ACCUMA_j ro — Receive data path eye surf accumulator A status register. Offset = 434Ch + (j * 400h); where j = 0h to 1h
  [25:16] EYESURF_ACCUMB — Receive data path eye surf accumulator B result.
  [9:0] EYESURF_ACCUMA — Receive data path eye surf accumulator A result.
0x4350 RX_BIST_SYNCCNT_PREG__RX_BIST_CONTROLS_PREG_j access per field — Receive BIST control register. Offset = 4350h + (j * 400h); where j = 0h to 1h
  [31:16] RX_BIST_SYNC_COUNT_PREG rw — Receive BIST synchronization count:
  [11:8] RX_BIST_MODE_PREG rw — Receive BIST mode:
  [4] RX_BIST_ERR_RESET_PREG wo — Receive BIST error clear:
  [1] RX_BIST_UDD_WR_CLEAR_PREG rw — Receive BIST User Defined Data (UDD) FIFO write pointer clear:
  [0] RX_BIST_EN_PREG rw — Receive BIST active high enable.
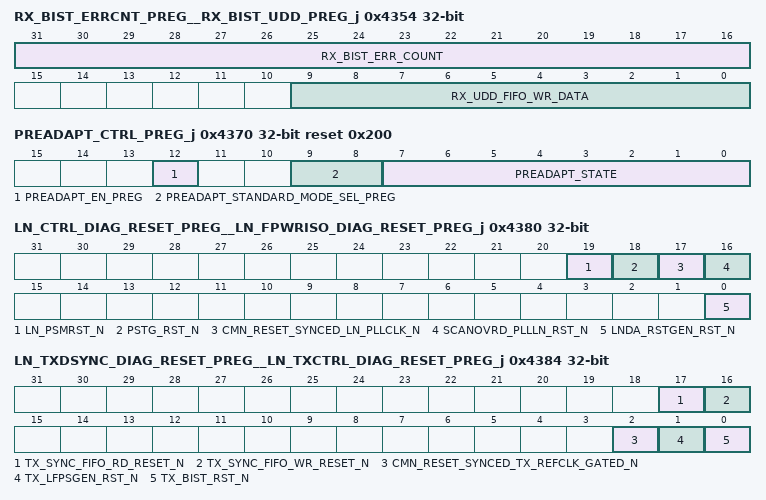
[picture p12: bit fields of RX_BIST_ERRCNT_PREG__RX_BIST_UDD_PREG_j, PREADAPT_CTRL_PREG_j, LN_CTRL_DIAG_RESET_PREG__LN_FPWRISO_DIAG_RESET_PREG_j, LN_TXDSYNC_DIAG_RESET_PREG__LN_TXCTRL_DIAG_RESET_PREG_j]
0x4354 RX_BIST_ERRCNT_PREG__RX_BIST_UDD_PREG_j access per field — Receive BIST user defined data (UDD) FIFO definition register. Offset = 4354h + (j * 400h); where j = 0h to 1h
  [31:16] RX_BIST_ERR_COUNT ro — Receive BIST accumulated error count.
  [9:0] RX_UDD_FIFO_WR_DATA wo — Receive BIST user defined data:
0x4360 LN_SPARE_REG_PREG_j — Local Lane spare register. Offset = 4360h + (j * 400h); where j = 0h to 1h
  [15:0] SPARE_PREG — Spare register bits assigned to lnda_sparecdb.
0x4370 PREADAPT_CTRL_PREG_j access per field reset 0x200 — Pre-adaptation control register. Offset = 4370h + (j * 400h); where j = 0h to 1h
  [12] PREADAPT_EN_PREG rw — Active high pre-adaptation enable.
  [9:8] PREADAPT_STANDARD_MODE_SEL_PREG rw — Pre-adaptation xcvr_standard_mode selection:
  [7:0] PREADAPT_STATE ro — Pre-adpatation current state:
0x4380 LN_CTRL_DIAG_RESET_PREG__LN_FPWRISO_DIAG_RESET_PREG_j ro — Lane fpwriso reset diagnostic register Offset = 4380h + (j * 400h); where j = 0h to 1h
  [19] LN_PSMRST_N — Current state of the ln_psmrst_n reset.
  [18] PSTG_RST_N — Current state of the pstg_rst_n reset.
  [17] CMN_RESET_SYNCED_LN_PLLCLK_N — Current state of the cmn_reset_synced_ln_pllclk_n reset.
  [16] SCANOVRD_PLLLN_RST_N — Current state of the scanovrd_pllln_rst_n reset.
  [0] LNDA_RSTGEN_RST_N — Current state of the lnda_rstgen_rst_n reset.
0x4384 LN_TXDSYNC_DIAG_RESET_PREG__LN_TXCTRL_DIAG_RESET_PREG_j ro — Lane Tx control reset diagnostic register Offset = 4384h + (j * 400h); where j = 0h to 1h
  [17] TX_SYNC_FIFO_RD_RESET_N — Current state of the tx_sync_fifo_rd_reset_n reset.
  [16] TX_SYNC_FIFO_WR_RESET_N — Current state of the tx_sync_fifo_wr_reset_n reset.
  [2] CMN_RESET_SYNCED_TX_REFCLK_GATED_N — Current state of the cmn_reset_synced_tx_refclk_gated_n reset.
  [1] TX_LFPSGEN_RST_N — Current state of the tx_lfpsgen_rst_n reset.
  [0] TX_BIST_RST_N — Current state of the tx_bist_rst_n reset.
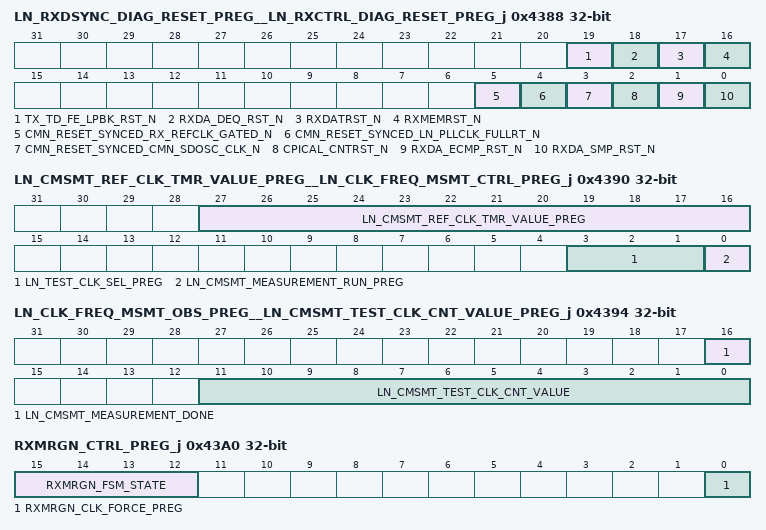
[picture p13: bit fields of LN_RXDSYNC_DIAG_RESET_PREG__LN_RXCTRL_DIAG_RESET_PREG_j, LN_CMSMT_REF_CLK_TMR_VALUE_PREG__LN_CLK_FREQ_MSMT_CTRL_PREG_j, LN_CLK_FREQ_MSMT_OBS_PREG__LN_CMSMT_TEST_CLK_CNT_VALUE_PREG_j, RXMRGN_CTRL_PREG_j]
0x4388 LN_RXDSYNC_DIAG_RESET_PREG__LN_RXCTRL_DIAG_RESET_PREG_j ro — Lane Rx control reset diagnostic register Offset = 4388h + (j * 400h); where j = 0h to 1h
  [19] TX_TD_FE_LPBK_RST_N — Current state of the tx_td_fe_lpbk_rst_n reset.
  [18] RXDA_DEQ_RST_N — Current state of the rxda_deq_rst_n reset.
  [17] RXDATRST_N — Current state of the rxdatrst_n reset.
  [16] RXMEMRST_N — Current state of the rxmemrst_n reset.
  [5] CMN_RESET_SYNCED_RX_REFCLK_GATED_N — Current state of the cmn_reset_synced_rx_refclk_gated_n reset.
  [4] CMN_RESET_SYNCED_LN_PLLCLK_FULLRT_N — Current state of the cmn_reset_synced_ln_pllclk_fullrt_n reset.
  [3] CMN_RESET_SYNCED_CMN_SDOSC_CLK_N — Current state of the cmn_reset_synced_cmn_sdosc_clk_n reset.
  [2] CPICAL_CNTRST_N — Current state of the cpical_cntrst_n reset.
  [1] RXDA_ECMP_RST_N — Current state of the rxda_ecmp_rst_n reset.
  [0] RXDA_SMP_RST_N — Current state of the rxda_smp_rst_n reset.
0x4390 LN_CMSMT_REF_CLK_TMR_VALUE_PREG__LN_CLK_FREQ_MSMT_CTRL_PREG_j — Register For Controlling Clock Frequency Measurement Module. Offset = 4390h + (j * 400h); where j = 0h to 1h
  [27:16] LN_CMSMT_REF_CLK_TMR_VALUE_PREG — Reference clock Timer Value
  [3:1] LN_TEST_CLK_SEL_PREG — Select Line For Clock Signal Muxing
  [0] LN_CMSMT_MEASUREMENT_RUN_PREG — Clock Frequency Measurement Enablign Signal.
0x4394 LN_CLK_FREQ_MSMT_OBS_PREG__LN_CMSMT_TEST_CLK_CNT_VALUE_PREG_j ro — Status Register Indicating the test clock count value from Clock Frequency Measurement Module. Offset = 4394h + (j * 400h); where j = 0h to 1h
  [16] LN_CMSMT_MEASUREMENT_DONE — Clock Frequency Measurement Done Output.
  [11:0] LN_CMSMT_TEST_CLK_CNT_VALUE — Test Clock Count value Output
0x43A0 RXMRGN_CTRL_PREG_j access per field — RX margining control and status register Offset = 43A0h + (j * 400h); where j = 0h to 1h
  [15:12] RXMRGN_FSM_STATE ro — ln_rxctrl_rxmrgn FSM state vector
  [0] RXMRGN_CLK_FORCE_PREG rw — When asserted,rxmrgb_clk remains on when whenever rxdatclk is on in power state where psc_rxmrgn_en is asserted.
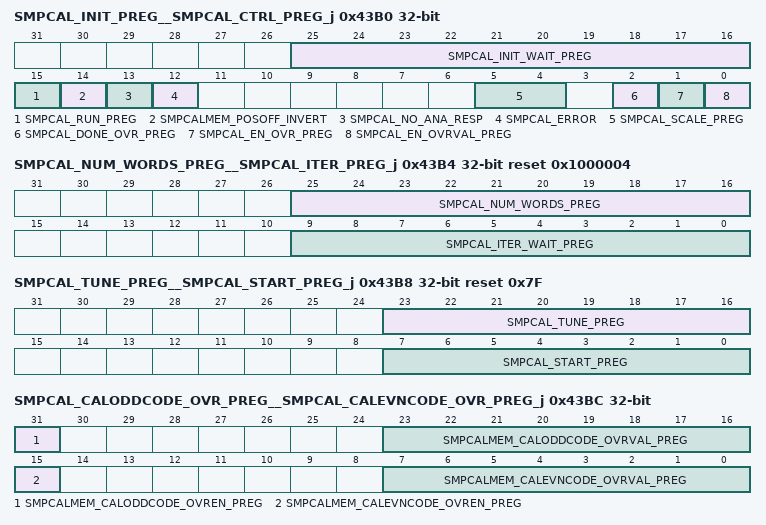
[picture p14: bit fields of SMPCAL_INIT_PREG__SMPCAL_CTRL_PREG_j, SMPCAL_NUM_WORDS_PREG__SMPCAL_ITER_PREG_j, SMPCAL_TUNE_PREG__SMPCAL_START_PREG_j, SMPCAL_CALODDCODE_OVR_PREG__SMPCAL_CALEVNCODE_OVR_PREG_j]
0x43B0 SMPCAL_INIT_PREG__SMPCAL_CTRL_PREG_j access per field — Data path sampler offset calibration control register. Offset = 43B0h + (j * 400h); where j = 0h to 1h
  [25:16] SMPCAL_INIT_WAIT_PREG rw — Data path sampler offset calibration initial wait timer.
  [15] SMPCAL_RUN_PREG rw — Data path sampler offset calibration manual start signal.
  [14] SMPCALMEM_POSOFF_INVERT rw — Data path sampler offset calibration positive offset correction inversion.
  [13] SMPCAL_NO_ANA_RESP ro — Data path sampler offset calibration no analog response flag.
  [12] SMPCAL_ERROR ro — Data path sampler offset calibration error flag.
  [5:4] SMPCAL_SCALE_PREG rw — Data path sampler offset calibration scale register.
  [2] SMPCAL_DONE_OVR_PREG rw — Data path sampler offset calibration done override.
  [1] SMPCAL_EN_OVR_PREG rw — Data path sampler offset calibration enable active high override enable.
  [0] SMPCAL_EN_OVRVAL_PREG rw — Data path sampler offset calibration enable active high override value.
0x43B4 SMPCAL_NUM_WORDS_PREG__SMPCAL_ITER_PREG_j reset 0x1000004 — Data path sampler offset calibration iteration timer register. Offset = 43B4h + (j * 400h); where j = 0h to 1h
  [25:16] SMPCAL_NUM_WORDS_PREG — Data path sampler offset calibration accumulation period timer.
  [9:0] SMPCAL_ITER_WAIT_PREG — Data path sampler offset calibration iteration wait timer.
0x43B8 SMPCAL_TUNE_PREG__SMPCAL_START_PREG_j reset 0x7F — Data path sampler offset calibration starting code register. Offset = 43B8h + (j * 400h); where j = 0h to 1h
  [23:16] SMPCAL_TUNE_PREG — Data path sampler offset calibration tuning offset.
  [7:0] SMPCAL_START_PREG — Data path sampler offset calibration start code.
0x43BC SMPCAL_CALODDCODE_OVR_PREG__SMPCAL_CALEVNCODE_OVR_PREG_j — Data path sampler offset calibration even code override register. Offset = 43BCh + (j * 400h); where j = 0h to 1h
  [31] SMPCALMEM_CALODDCODE_OVREN_PREG — Data path sampler offset calibration odd code active high override enable.
  [23:16] SMPCALMEM_CALODDCODE_OVRVAL_PREG — When smpcalmem_caloddcode_ovren_preg is asserted high, this value overrides the rxda_smp_caloddmag and rxda_smp_caloddposoff analog controls as follows:
  [15] SMPCALMEM_CALEVNCODE_OVREN_PREG — Data path sampler offset calibration even code active high override enable.
  [7:0] SMPCALMEM_CALEVNCODE_OVRVAL_PREG — When smpcalmem_calevncode_ovren_preg is asserted high, this value overrides the rxda_smp_calevnmag and rxda_smp_calevnposoff analog controls as follows:
0x43C0 SMPCAL_CALODDCODE_PREG__SMPCAL_CALEVNCODE_PREG_j ro — Data path sampler offset calibration even slicer status register. Offset = 43C0h + (j * 400h); where j = 0h to 1h
  [31] SMPCAL_ODDDONE — Data path sampler offset odd calibration active high complete flag.
  [23:16] SMPCAL_CALODDCODE — Data path sampler offset calibration odd calibration result.
  [15] SMPCAL_EVNDONE — Data path sampler offset even calibration active high complete flag.
  [7:0] SMPCAL_CALEVNCODE — Data path sampler offset calibration even calibration result.
0x43C4 SMPCAL_STATE_PREG_j ro — Data path sampler offset calibration master state machine state vector status register. Offset = 43C4h + (j * 400h); where j = 0h to 1h
  [9:0] SMPCAL_STATE — Data path sampler offset calibration master state machine state vector.
0x43D0 DEQ_BMPR_TAU_CTRL2_PREG__DEQ_BMPR_TAU_CTRL1_PREG_j reset 0x5 — Receive data path equalization (DEQ) bumper TAU algorithm control register 1 Offset = 43D0h + (j * 400h); where j = 0h to 1h
  [25:16] BMPR_TAU_ERROR_THRESH_PREG — Bumper TAU algorithm error accumulation threshold.
  [15] BMPR_TAU_DIR_PREG — Bumper TAU algorithm EPI initial direction control.
  [13:12] BMPR_TAU_PING_PONG_EN_PREG — Bumper TAU ping pong enable register.
  [3:0] BMPR_TAU_EPIOFFSET_PREG — Bumper TAU algorithm 4 bit signed offset for EPI.
0x43D4 DEQ_TAU_MAINT_VTH_PREG__DEQ_TAU_ACQ_VTH_PREG_j — Receive data path equalization (DEQ) TAU algorithm acquisition voltage threshold control register Offset = 43D4h + (j * 400h); where j = 0h to 1h
  [30:24] TAU_MAINTECMPA_VTH_PREG — TAU algorithm voltage threshold control register for both error comparators A and B, binary encoded, used for maintenance for bumper TAU during ST_BMPR_TAU_ACCUM_A, and for apparent center and maintenace for block TAU during ST_BLK_TAU_ACCUM_A.
  [22:16] TAU_MAINTECMPB_VTH_PREG — TAU algorithm voltage threshold control register for both error comparators A and B, binary encoded, used for maintenance for bumper TAU during ST_BMPR_TAU_ACCUM_B, and for apparent center and maintenace for block TAU during ST_BLK_TAU_ACCUM_B.
  [14:8] TAU_ECMPA_VTH_PREG — TAU algorithm voltage threshold control register for both error comparators A and B, binary encoded, used for initial acquisition for bumper TAU during ST_BMPR_TAU_ACCUM_A, and block TAU during ST_BLK_TAU_ACCUM_A.
  [6:0] TAU_ECMPB_VTH_PREG — TAU algorithm voltage threshold control register for both error comparators A and B, binary encoded, used for initial acquisition for bumper TAU during ST_BMPR_TAU_ACCUM_B, and block TAU during ST_BLK_TAU_ACCUM_B.
0x43D8 DEQ_BLK_TAU_CTRL2_PREG__DEQ_BLK_TAU_CTRL1_PREG_j access per field reset 0x2E2E — Receive data path equalization (DEQ) block TAU algorithm control register 1 Offset = 43D8h + (j * 400h); where j = 0h to 1h
  [30:24] BLK_TAU_EPISHIFT_OPTCENT ro — Block TAU algorithm optimal EPI phase shift obtained from AC_TAU
  [23] BLK_TAU_EPISHIFT_OPTCENT_OVREN_PREG rw — Block TAU algorithm EPI phase shift override enable used for maintenance
  [22:16] BLK_TAU_EPISHIFT_OPTCENT_OVRD_PREG rw — Block TAU algorithm EPI phase shift override value used for maintenance
  [15:12] BLK_TAU_EPIOFFSETA_PREG rw — Block TAU algorithm 4 bit signed offset for EPI, used for accumulation during ST_TAU3_ACCUM_A during initial acquisition.
  [11:8] BLK_TAU_EPIOFFSETB_PREG rw — Block TAU algorithm 4 bit signed offset for EPI, used for accumulation during ST_TAU3_ACCUM_B during initial acquisition.
  [7:4] BLK_TAU_MAINT_EPIOFFSETA_PREG rw — Block TAU algorithm 4 bit signed offset for EPI, used for accumulation during ST_TAU3_ACCUM_A during AC_TAU and maintenance.
  [3:0] BLK_TAU_MAINT_EPIOFFSETB_PREG rw — Block TAU algorithm 4 bit signed offset for EPI, used for accumulation during ST_TAU3_ACCUM_B during AC_TAU and maintenance.
0x43DC DEQ_BLK_TAU_CTRL4_PREG__DEQ_BLK_TAU_CTRL3_PREG_j access per field reset 0xA8 — Receive data path equalization (DEQ) block TAU algorithm control register 3 Offset = 43DCh + (j * 400h); where j = 0h to 1h
  [22:16] BLK_TAU_DPI_OPTCENT ro — Block TAU algorithm optimal DPI phase obtained from initial acquisition
  [13:10] BLK_TAU_PATTERN_MASK_PREG rw — Block TAU algorithm pattern filter mask.
  [9] BLK_TAU_AC_BYPASS_CONCUR_PREG rw — Block TAU algorithm bypass concur register.
  [8:0] BLK_TAU_AC_MINITER_PREG rw — Block TAU algorithm minimum iterations of AC_TAU and concur processes during the apparent center states.
